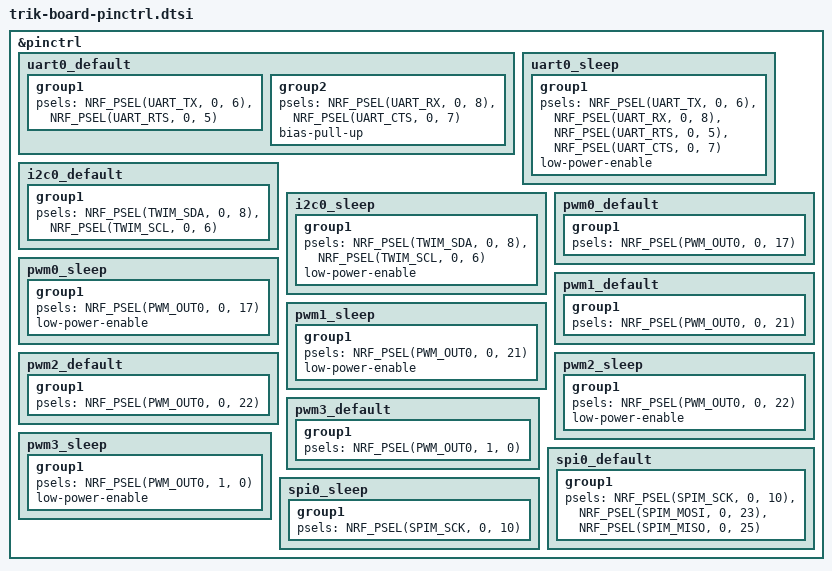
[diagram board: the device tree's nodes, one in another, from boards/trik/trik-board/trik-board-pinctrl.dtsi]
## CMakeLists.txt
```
cmake_minimum_required(VERSION 3.20.0)
find_package(Zephyr REQUIRED HINTS $ENV{ZEPHYR_BASE})

project(trik-nrf52833)

target_include_directories(app PRIVATE 
    src/usb
    src/periphery
    src/i2c
)

target_sources(app PRIVATE 
    src/main.c
    src/periphery/encoder.c
    src/periphery/saadc.c
    src/periphery/pwm.c
    src/periphery/port_table.c
    src/periphery/analog_sensor.c
    src/periphery/periphery_handler.c
    src/usb/internal/usb_device_next.c
    src/usb/internal/raw_usbd_init.c
    src/usb/internal/bt_hci_usb.c
    src/usb/protocol_schema.c
    src/i2c/i2c_handler.c
)

target_include_directories(app PRIVATE src)
```

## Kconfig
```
source "Kconfig.zephyr"

menu "Raw USB Configuration"

config RAW_USB_VID
    hex "Raw USB Vendor ID"
    default 0x2FE9
    help
      Vendor ID for the raw USB device.

config RAW_USB_PID
    hex "Raw USB Product ID"
    default 0x0100
    help
      Product ID for the raw USB device.

config RAW_USB_MANUFACTURER
    string "USB Manufacturer string"
    default "MyCompany"

config RAW_USB_PRODUCT
    string "USB Product string"
    default "Raw_Encoder_Device"

config RAW_USB_VERSION
    string "Firmware version string"
    default "1.0.0"
    help
      Version string reported over the GET_VERSION vendor control request.
      Must match the firmware.version marker in the distro repo.

config RAW_USB_SELF_POWERED
    bool "Set USB Self-Powered attribute"
    default n
    help
      Set to y if the device has an external power source.

config CUSTOM_USBD_MAX_POWER
    int "Maximum power consumption (mA)"
    default 100
    range 0 500

config USBD_RAW_BUF_POOL
    bool "Use dedicated buffer pool for Raw USB"
    default y

config USB_PROTO_RX_COUNT
    int "Number of RX buffers"
    default 12

config USB_PROTO_RX_MAX_SIZE
    int "Max payload size"
    default 256

config RAW_USB_TELEMETRY_ISO
    bool "Send telemetry over an isochronous IN endpoint"
    default n
    help
      Select the transport used for periodic periphery telemetry.

      When disabled (default), telemetry packets are sent over the shared
      BULK IN endpoint together with the request/response stream. Delivery
      timing is then paced by the host and is not guaranteed.

      When enabled, an additional isochronous IN endpoint is added to the
      vendor interface and telemetry frames are sent once per USB full-speed
      frame (1 kHz) with hardware-paced cadence. The request/response stream
      stays on BULK.

      Endpoint address is configurable with RAW_USB_TELEMETRY_ISO_EP. On
      nRF52 the isochronous IN endpoint is fixed at 0x88.

config RAW_USB_TELEMETRY_ISO_EP
    hex "Telemetry isochronous IN endpoint address"
    default 0x88

endmenu

menu "BLE HCI USB Dongle Configuration"

config TRIK_BT_HCI_LOG_LEVEL
    int "BT HCI class log level (0=OFF..4=DBG)"
    default 3
    range 0 4

config TRIK_BT_HCI_TX_STACK_SIZE
    int "HCI TX thread stack size (bytes)"
    default 512

config TRIK_BT_HCI_RX_STACK_SIZE
    int "HCI RX thread stack size (bytes)"
    default 512

config TRIK_BT_HCI_RX_THREAD_PRIORITY
    int "HCI RX thread priority (cooperative)"
    default 8

config TRIK_BT_HCI_TX_THREAD_PRIORITY
    int "HCI TX thread priority (cooperative)"
    default 8

endmenu
```

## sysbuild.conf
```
SB_CONFIG_BOOTLOADER_MCUBOOT=y
SB_CONFIG_PARTITION_MANAGER=y
SB_CONFIG_MCUBOOT_MODE_SINGLE_APP=y
SB_CONFIG_MCUBOOT_APP_SYNC_UPDATEABLE_IMAGES=n
```

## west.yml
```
manifest:
  remotes:
    - name: nrfconnect
      url-base: https://github.com/nrfconnect

  projects:
    - name: sdk-nrf
      revision: v3.2.3
      path: nrf
      remote: nrfconnect
      import:
        name-allowlist:
          - zephyr
          - hal_nordic
          - nrfxlib
          - mbedtls
          - cmsis_6
          - mcuboot
          - oberon-psa-crypto
          - zcbor
```

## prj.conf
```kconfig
CONFIG_USB_DEVICE_STACK_NEXT=y
CONFIG_RAW_USB_SELF_POWERED=y
CONFIG_NRFX_GPIOTE_NUM_OF_EVT_HANDLERS=8
CONFIG_UDC_DRIVER=y
# The nRF UDC re-arms the isochronous IN endpoint only on SOF interrupts
# (ev_sof_handler in udc_nrf.c). Without CONFIG_UDC_ENABLE_SOF only the first
# ISO frame is ever transmitted. Telemetry now defaults to BULK (host-paced);
# if the isochronous transport is used again, uncomment this line together
# with CONFIG_RAW_USB_TELEMETRY_ISO at the bottom.
CONFIG_UDC_ENABLE_SOF=y
CONFIG_NRFX_GPIOTE0=y
CONFIG_RAW_USB_MANUFACTURER="trik"
CONFIG_RAW_USB_PRODUCT="periphery-module"
CONFIG_DEBUG_THREAD_INFO=n
CONFIG_THREAD_MONITOR=n
CONFIG_NRFX_SAADC=y
CONFIG_NRFX_GPPI=y
CONFIG_NRFX_TIMER=y
CONFIG_PWM=y
CONFIG_BT=y
CONFIG_BT_HCI_RAW=y
CONFIG_BT_LL_SOFTDEVICE_MULTIROLE=y
CONFIG_BT_MAX_CONN=1
# CONFIG_USBD_BT_HCI not set — app uses its own bt_hci_usb.c
CONFIG_BOOTLOADER_MCUBOOT=y
CONFIG_MCUBOOT_IMGTOOL_SIGN_VERSION="1.0.0"
CONFIG_RAW_USB_VERSION="1.0.0"

CONFIG_NRFX_TWIS=y

# Telemetry transport. Default = BULK: snapshots share the BULK IN 0x81
# endpoint with the request/response stream and are paced by the host (pull).
# The isochronous transport (ISO IN 0x88, one snapshot per 1 ms USB frame)
# requires CONFIG_UDC_ENABLE_SOF=y above and is kept commented out for now.
CONFIG_RAW_USB_TELEMETRY_ISO=y

CONFIG_NETWORKING=y
CONFIG_IEEE802154=y
CONFIG_NET_L2_IEEE802154=y
```

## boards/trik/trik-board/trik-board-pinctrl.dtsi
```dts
&pinctrl {
	uart0_default: uart0_default {
		group1 {
			psels = <NRF_PSEL(UART_TX, 0, 6)>,
				<NRF_PSEL(UART_RTS, 0, 5)>;
		};

		group2 {
			psels = <NRF_PSEL(UART_RX, 0, 8)>,
				<NRF_PSEL(UART_CTS, 0, 7)>;
			bias-pull-up;
		};
	};

	uart0_sleep: uart0_sleep {
		group1 {
			psels = <NRF_PSEL(UART_TX, 0, 6)>,
				<NRF_PSEL(UART_RX, 0, 8)>,
				<NRF_PSEL(UART_RTS, 0, 5)>,
				<NRF_PSEL(UART_CTS, 0, 7)>;
			low-power-enable;
		};
	};

	i2c0_default: i2c0_default {
		group1 {
			psels = <NRF_PSEL(TWIM_SDA, 0, 8)>,
				<NRF_PSEL(TWIM_SCL, 0, 6)>;
		};
	};

	i2c0_sleep: i2c0_sleep {
		group1 {
			psels = <NRF_PSEL(TWIM_SDA, 0, 8)>,
				<NRF_PSEL(TWIM_SCL, 0, 6)>;
			low-power-enable;
		};
	};

	pwm0_default: pwm0_default {
		group1 { psels = <NRF_PSEL(PWM_OUT0, 0, 17)>; };
	};

	pwm0_sleep: pwm0_sleep {
		group1 {
			psels = <NRF_PSEL(PWM_OUT0, 0, 17)>;
			low-power-enable;
		};
	};

	pwm1_default: pwm1_default {
		group1 { psels = <NRF_PSEL(PWM_OUT0, 0, 21)>; };
	};

	pwm1_sleep: pwm1_sleep {
		group1 {
			psels = <NRF_PSEL(PWM_OUT0, 0, 21)>;
			low-power-enable;
		};
	};

	pwm2_default: pwm2_default {
		group1 { psels = <NRF_PSEL(PWM_OUT0, 0, 22)>; };
	};

	pwm2_sleep: pwm2_sleep {
		group1 {
			psels = <NRF_PSEL(PWM_OUT0, 0, 22)>;
			low-power-enable;
		};
	};

	pwm3_default: pwm3_default {
		group1 { psels = <NRF_PSEL(PWM_OUT0, 1, 0)>; };
	};

	pwm3_sleep: pwm3_sleep {
		group1 {
			psels = <NRF_PSEL(PWM_OUT0, 1, 0)>;
			low-power-enable;
		};
	};

	spi0_default: spi0_default {
		group1 {
			psels = <NRF_PSEL(SPIM_SCK, 0, 10)>,
					<NRF_PSEL(SPIM_MOSI, 0, 23)>,
					<NRF_PSEL(SPIM_MISO, 0, 25)>;
		};
	};

	spi0_sleep: spi0_sleep {
		group1 {
			psels = <NRF_PSEL(SPIM_SCK, 0, 10)>;
		};
	};
};
```

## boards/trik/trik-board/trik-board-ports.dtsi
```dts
/ {
	ports {
		#address-cells = <1>;
		#size-cells = <0>;

		port_e1: port@0 {
			compatible = "trik,encoder-port";
			reg = <0>;
			port-name = "E1";

			a-gpios = <&gpio0 7 (GPIO_PULL_UP | GPIO_ACTIVE_LOW)>;
			b-gpios = <&gpio1 9 (GPIO_PULL_UP | GPIO_ACTIVE_LOW)>;
		};

		port_e2: port@1 {
			compatible = "trik,encoder-port";
			reg = <1>;
			port-name = "E2";

			a-gpios = <&gpio1 7 (GPIO_PULL_UP | GPIO_ACTIVE_LOW)>;
			b-gpios = <&gpio1 6 (GPIO_PULL_UP | GPIO_ACTIVE_LOW)>;
		};

		port_e3: port@2 {
			compatible = "trik,encoder-port";
			reg = <2>;
			port-name = "E3";

			a-gpios = <&gpio0 12 (GPIO_PULL_UP | GPIO_ACTIVE_LOW)>;
			b-gpios = <&gpio0 11 (GPIO_PULL_UP | GPIO_ACTIVE_LOW)>;
		};

		port_e4: port@3 {
			compatible = "trik,encoder-port";
			reg = <3>;
			port-name = "E4";

			a-gpios = <&gpio1 4 (GPIO_PULL_UP | GPIO_ACTIVE_LOW)>;
			b-gpios = <&gpio1 2 (GPIO_PULL_UP | GPIO_ACTIVE_LOW)>;
		};

		port_a1: port@4 {
			compatible = "trik,analog-port";
			reg = <4>;
			port-name = "A1";

			enable = <&gpio0 0 GPIO_ACTIVE_HIGH>;
			io-channels = <&adc 3>; /* P0.05 */
			out = <&gpio0 27 GPIO_ACTIVE_HIGH>;
		};

		port_a2: port@5 {
			compatible = "trik,analog-port";
			reg = <5>;
			port-name = "A2";

			enable = <&gpio0 1 GPIO_ACTIVE_HIGH>;
			io-channels = <&adc 2>; /* P0.04 */
			out = <&gpio0 26 GPIO_ACTIVE_HIGH>;
		};

		port_a3: port@6 {
			compatible = "trik,analog-port";
			reg = <6>;
			port-name = "A3";

			enable = <&gpio0 9 GPIO_ACTIVE_HIGH>;
			io-channels = <&adc 6>; /* P0.30 */
			out = <&gpio0 13 GPIO_ACTIVE_HIGH>;
		};

		port_a4: port@7 {
			compatible = "trik,analog-port";
			reg = <7>;
			port-name = "A4";

			enable = <&gpio0 10 GPIO_ACTIVE_HIGH>;
			io-channels = <&adc 7>; /* P0.31 */
			out = <&gpio0 14 GPIO_ACTIVE_HIGH>;
		};

		port_a5: port@8 {
			compatible = "trik,analog-port";
			reg = <8>;
			port-name = "A5";

			enable = <&gpio0 23 GPIO_ACTIVE_HIGH>;
			io-channels = <&adc 4>; /* P0.28 */
			out = <&gpio0 15 GPIO_ACTIVE_HIGH>;
		};

		port_a6: port@9 {
			compatible = "trik,analog-port";
			reg = <9>;
			port-name = "A6";

			enable = <&gpio0 25 GPIO_ACTIVE_HIGH>;
			io-channels = <&adc 5>; /* P0.29 */
			out = <&gpio0 16 GPIO_ACTIVE_HIGH>;
		};

		port_a7: port@a {
			compatible = "trik,servo-port";
			reg = <0xa>;
			port-name = "A7";

			enable = <&gpio1 1 GPIO_ACTIVE_HIGH>;
			in = <&gpio0 3 GPIO_ACTIVE_HIGH>;
			pwms = <&pwm0 0 PWM_MSEC(20) PWM_POLARITY_NORMAL>;
		};

		port_a8: port@b {
			compatible = "trik,servo-port";
			reg = <0xb>;
			port-name = "A8";

			enable = <&gpio1 3 GPIO_ACTIVE_HIGH>;
			in = <&gpio0 2 GPIO_ACTIVE_HIGH>;
			pwms = <&pwm1 0 PWM_MSEC(20) PWM_POLARITY_NORMAL>;
		};

		port_a9: port@c {
			compatible = "trik,servo-port";
			reg = <0xc>;
			port-name = "A9";

			enable = <&gpio0 19 GPIO_ACTIVE_HIGH>;
			in = <&gpio0 20 GPIO_ACTIVE_HIGH>;
			pwms = <&pwm2 0 PWM_MSEC(20) PWM_POLARITY_NORMAL>;
		};

		port_a10: port@d {
			compatible = "trik,servo-port";
			reg = <0xd>;
			port-name = "A10";

			enable = <&gpio1 5 GPIO_ACTIVE_HIGH>;
			in = <&gpio0 24 GPIO_ACTIVE_HIGH>;
			pwms = <&pwm3 0 PWM_MSEC(20) PWM_POLARITY_NORMAL>;
		};
	};
};
```

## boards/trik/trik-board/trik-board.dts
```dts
/dts-v1/;

#include <nordic/nrf52833_qiaa.dtsi>
#include "trik-board-pinctrl.dtsi"
#include "trik-board-ports.dtsi"
#include <zephyr/dt-bindings/pwm/pwm.h>
#include <zephyr/dt-bindings/gpio/gpio.h>
#include <zephyr/dt-bindings/pinctrl/nrf-pinctrl.h>

/ {
	model = "Peripheral module for a mobile robot";
	compatible = "trik,trik-board";

	usb_raw_cmd: usb_raw_0 {
		compatible = "zephyr,usb-raw";
		status = "okay";
		bulk-in-ep = <0x81>;
		bulk-out-ep = <0x01>;
		intr-out-ep = <0x03>;
	};

	analog_sensors {
		analog_a1: analog-sensor-a1 {
			compatible = "trik,analog-sensor";
			port = <&port_a1>;
		};

		analog_a2: analog-sensor-a2 {
			compatible = "trik,analog-sensor";
			port = <&port_a2>;
		};

		analog_a3: analog-sensor-a3 {
			compatible = "trik,analog-sensor";
			port = <&port_a3>;
		};

		analog_a4: analog-sensor-a4 {
			compatible = "trik,analog-sensor";
			port = <&port_a4>;
		};

		analog_a5: analog-sensor-a5 {
			compatible = "trik,analog-sensor";
			port = <&port_a5>;
		};

		analog_a6: analog-sensor-a6 {
			compatible = "trik,analog-sensor";
			port = <&port_a6>;
		};
	};

	chosen {
		zephyr,console = &uart0;
		zephyr,shell-uart = &uart0;
		zephyr,bt-mon-uart = &uart0;
		zephyr,bt-c2h-uart = &uart0;
		zephyr,sram = &sram0;
		zephyr,flash = &flash0;
		zephyr,ieee802154 = &ieee802154;
	};
};

&flash0 {
	status = "okay";
	partitions {
		compatible = "fixed-partitions";
		#address-cells = <1>;
		#size-cells = <1>;

		slot0_partition: partition@10000 {
			label = "image-0";
			reg = <0x00010000 0x00070000>;
		};
	};
};

&reg1 {
	regulator-initial-mode = <NRF5X_REG_MODE_DCDC>;
};

&adc {
	zephyr,deferred-init;
	status = "okay";
};

&uicr {
	status = "okay";
	gpio-as-nreset;
};

&nfct {
	status = "disabled";
};

&gpiote {
	status = "okay";
};

&gpio0 {
	status = "okay";
};

&gpio1 {
	status = "okay";
};

&uart0 {
	compatible = "nordic,nrf-uarte";
	status = "disabled";
	current-speed = <115200>;
	pinctrl-0 = <&uart0_default>;
	pinctrl-1 = <&uart0_sleep>;
	pinctrl-names = "default", "sleep";
};

&i2c1 {
	compatible = "nordic,nrf-twi";
	status = "disabled";
	pinctrl-0 = <&i2c0_default>;
	pinctrl-1 = <&i2c0_sleep>;
	pinctrl-names = "default", "sleep";
};

&pwm0 {
	status = "okay";
	pinctrl-0 = <&pwm0_default>;
	pinctrl-1 = <&pwm0_sleep>;
	pinctrl-names = "default", "sleep";
};

&pwm1 {
	status = "okay";
	pinctrl-0 = <&pwm1_default>;
	pinctrl-1 = <&pwm1_sleep>;
	pinctrl-names = "default", "sleep";
};

&pwm2 {
	status = "okay";
	pinctrl-0 = <&pwm2_default>;
	pinctrl-1 = <&pwm2_sleep>;
	pinctrl-names = "default", "sleep";
};

&pwm3 {
	status = "okay";
	pinctrl-0 = <&pwm3_default>;
	pinctrl-1 = <&pwm3_sleep>;
	pinctrl-names = "default", "sleep";
};

&ieee802154 {
	status = "okay";
};

zephyr_udc0: &usbd {
	compatible = "nordic,nrf-usbd";
	status = "okay";
};

&spi0 {
	status = "disabled";
	pinctrl-0 = <&spi0_default>;
	pinctrl-1 = <&spi0_sleep>;
	pinctrl-names = "default", "sleep";
	cs-gpios = <&gpio0 9 0>;
};
```

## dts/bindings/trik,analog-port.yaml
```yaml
description: TRIK analog port
compatible: "trik,analog-port"
include: [base.yaml, trik-port-common.yaml]

properties:
  io-channels:
    type: phandle-array
    required: true
  out:
    type: phandle-array
    specifier-space: gpio
    required: true
```

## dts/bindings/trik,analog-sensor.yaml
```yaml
description: TRIK analog sensor
compatible: "trik,analog-sensor"
include: [base.yaml]

properties:
  port:
    type: phandle
    required: true
```

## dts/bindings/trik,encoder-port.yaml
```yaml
description: TRIK encoder port
compatible: "trik,encoder-port"
include: [base.yaml, trik-port-common.yaml]

properties:
  a-gpios:
    type: phandle-array
    specifier-space: gpio
    required: true
  b-gpios:
    type: phandle-array
    specifier-space: gpio
    required: true
```

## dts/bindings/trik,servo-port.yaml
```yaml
description: TRIK servo port
compatible: "trik,servo-port"
include: [base.yaml, trik-port-common.yaml]

properties:
  in:
    type: phandle-array
    specifier-space: gpio
    required: true
  pwms:
    type: phandle-array
    required: true
```

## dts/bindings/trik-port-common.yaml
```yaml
properties:
  port-name:
    type: string
    required: true
  enable:
    type: phandle-array
    specifier-space: gpio
```

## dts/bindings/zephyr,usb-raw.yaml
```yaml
description: USB Raw bulk interface (Custom Vendor Class)
compatible: "zephyr,usb-raw"

include: [base.yaml]

properties:
  bulk-in-ep:
    type: int
    required: true
    description: Address of the IN endpoint (e.g., 0x81)
  bulk-out-ep:
    type: int
    required: true
    description: Address of the OUT endpoint (e.g., 0x01)
  intr-out-ep:
    type: int
    required: false
    description: Address of the interrupt OUT endpoint for control commands (e.g., 0x03)
  
```

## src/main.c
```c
/* Copyright 2026 CyberTech Labs Ltd.
 *
 * Licensed under the Apache License, Version 2.0 (the "License");
 * you may not use this file except in compliance with the License.
 * You may obtain a copy of the License at
 *
 *     http://www.apache.org/licenses/LICENSE-2.0
 *
 * Unless required by applicable law or agreed to in writing, software
 * distributed under the License is distributed on an "AS IS" BASIS,
 * WITHOUT WARRANTIES OR CONDITIONS OF ANY KIND, either express or implied.
 * See the License for the specific language governing permissions and
 * limitations under the License. */

#include <string.h>
#include <zephyr/kernel.h>
#include <zephyr/logging/log.h>
#include "usb/usb_device_api.h"
#include "periphery_addresses.h"
#include "i2c_handler.h"

LOG_MODULE_REGISTER(usb_raw_echo, LOG_LEVEL_INF);

int main(void)
{
	int ret = 0;
	ret = enable_usb_device_next();
	if (ret != 0) {
		LOG_ERR("Failed to enable USB device support");
		return 0;
	}

	ret = init_periphery();

	if (ret != 0) {
		LOG_ERR("Failed to enable periphery");
		return 0;
	}

	ret = init_i2c_transport();
	if (ret != 0) {
		LOG_ERR("Failed to enable I2C transport");
		return 0;
	}

	while (1) {
		k_sleep(K_FOREVER);
	}

	return 0;
}
```
